# STM32N645 register map
File version: 1.0
CPU: CM55 r0p1, little endian, no MPU, FPU, vendor SysTick, 8 interrupt priority bits
Registers are 32-bit, read-write, reset 0x0 unless marked. A register's access mark holds for its fields unless they carry their own. Offsets are from the block's base; [hi:lo] are bit positions; lines under a group give offsets from that group; {n}, {i} and the like mark numbered series.

## I3C1 — Improved inter-integrated circuit
Base 0x40006000
Same registers: I3C2 0x40006400, I3C1_S 0x50006000, I3C2_S 0x50006400
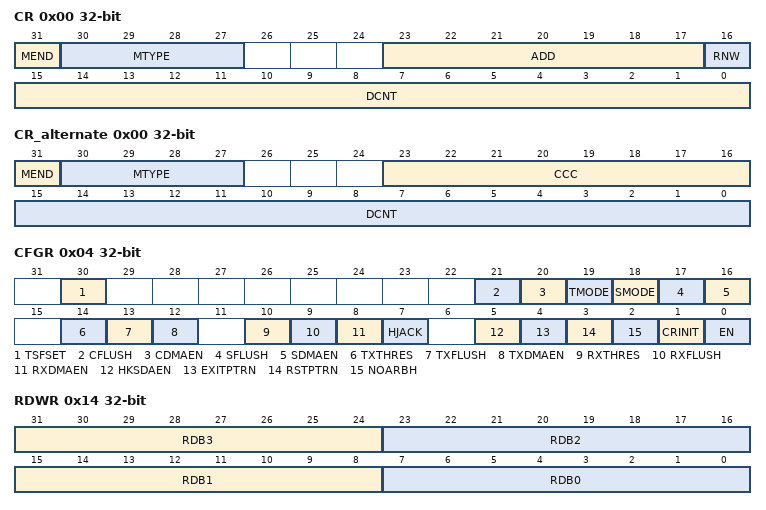
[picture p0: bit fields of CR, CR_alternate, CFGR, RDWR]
0x00 CR wo — I3C message control register
  [31] MEND — Message end type / last message of a frame (when the I3C acts as controller)
  [30:27] MTYPE — Message type (whatever I3C acts as controller/target)
  [23:17] ADD — 7-bit I3C dynamic / I less than sup>2 less than /sup>C static target address (when I3C acts as controller)
  [16] RNW — Read / non-write message (when I3C acts as controller)
  [15:0] DCNT — Count of data to transfer during a read or write message, in bytes (whatever I3C acts as controller/target)
0x00 CR_alternate wo (alternate view of CR) — I3C message control register
  [31] MEND — Message end type / last message of a frame (when I3C acts as controller)
  [30:27] MTYPE — Message type (when I3C acts as controller)
  [23:16] CCC — 8-bit CCC code (when I3C acts as controller)
  [15:0] DCNT — Count of related data to the CCC command to transfer as CCC defining bytes, or CCC sub-command bytes, or CCC data bytes, in bytes
0x04 CFGR access per field — I3C configuration register
  [30] TSFSET wo — Frame transfer set (software trigger) (when I3C acts as controller)
  [21] CFLUSH wo — C-FIFO flush (when I3C acts as controller)
  [20] CDMAEN rw — C-FIFO DMA request enable (when I3C acts as controller)
  [19] TMODE rw — Transmit mode (when I3C acts as controller)
  [18] SMODE rw — S-FIFO enable / status receive mode (when I3C acts as controller)
  [17] SFLUSH wo — S-FIFO flush (when I3C acts as controller)
  [16] SDMAEN rw — S-FIFO DMA request enable (when I3C acts as controller)
  [14] TXTHRES rw — TX-FIFO threshold (whatever I3C acts as controller/target)
  [13] TXFLUSH wo — TX-FIFO flush (whatever I3C acts as controller/target)
  [12] TXDMAEN rw — TX-FIFO DMA request enable (whatever I3C acts as controller/target)
  [10] RXTHRES rw — RX-FIFO threshold (whatever I3C acts as controller/target)
  [9] RXFLUSH wo — RX-FIFO flush (whatever I3C acts as controller/target)
  [8] RXDMAEN rw — RX-FIFO DMA request enable (whatever I3C acts as controller/target)
  [7] HJACK rw — Hot-join request acknowledge (when I3C acts as a controller)
  [5] HKSDAEN rw — High-keeper enable on SDA line (when I3C acts as a controller)
  [4] EXITPTRN rw — HDR exit pattern enable (when I3C acts as a controller)
  [3] RSTPTRN rw — HDR reset pattern enable (when I3C acts as a controller)
  [2] NOARBH rw — No arbitrable header after a start (when I3C acts as a controller)
  [1] CRINIT rw — Initial controller/target role
  [0] EN rw — I3C enable (whatever I3C acts as controller/target)
0x10 RDR ro — I3C receive data byte register
  [7:0] RDB0 — 8-bit received data on I3C bus.
0x14 RDWR ro — I3C receive data word register
  [31:24] RDB3 — 8-bit received data (latest byte on I3C bus).
  [23:16] RDB2 — 8-bit received data (next byte after RDB1 on I3C bus).
  [15:8] RDB1 — 8-bit received data (next byte after RDB0 on I3C bus).
  [7:0] RDB0 — 8-bit received data (earliest byte on I3C bus).
0x18 TDR wo — I3C transmit data byte register
  [7:0] TDB0 — 8-bit data to transmit on I3C bus.
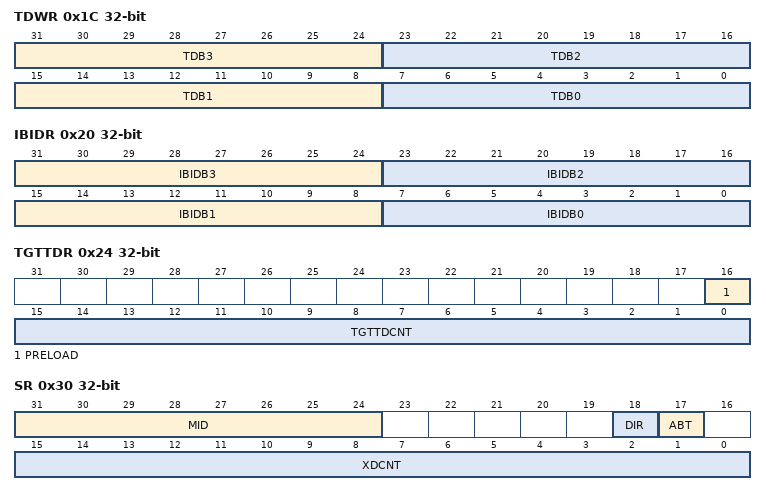
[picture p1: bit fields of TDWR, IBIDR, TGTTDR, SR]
0x1C TDWR wo — I3C transmit data word register
  [31:24] TDB3 — 8-bit transmit data (latest byte on I3C bus).
  [23:16] TDB2 — 8-bit transmit data (next byte after TDB1[7:0] on I3C bus).
  [15:8] TDB1 — 8-bit transmit data (next byte after TDB0[7:0] on I3C bus).
  [7:0] TDB0 — 8-bit transmit data (earliest byte on I3C bus)
0x20 IBIDR — I3C IBI payload data register
  [31:24] IBIDB3 — 8-bit IBI payload data (latest byte on I3C bus).
  [23:16] IBIDB2 — 8-bit IBI payload data (next byte on I3C bus after IBIDB1[7:0]).
  [15:8] IBIDB1 — 8-bit IBI payload data (next byte on I3C bus after IBIDB0[7:0]).
  [7:0] IBIDB0 — 8-bit IBI payload data (earliest byte on I3C bus, MDB[7:0] mandatory data byte).
0x24 TGTTDR — I3C target transmit configuration register
  [16] PRELOAD — Preload of the TX-FIFO (when I3C is configured as target)
  [15:0] TGTTDCNT — Transmit data counter, in bytes (when I3C is configured as target)
0x30 SR ro — I3C status register
  [31:24] MID — Message identifier/counter of a given frame (when the I3C acts as controller)
  [18] DIR — Message direction
  [17] ABT — A private read message is ended prematurely by the target (when the I3C acts as controller)
  [15:0] XDCNT — Data counter
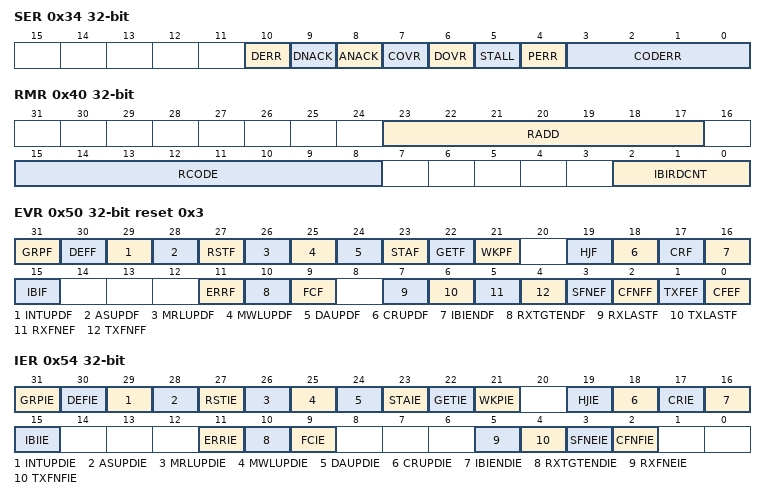
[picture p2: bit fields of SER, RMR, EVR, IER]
0x34 SER ro — I3C status error register
  [10] DERR — Data error (when the I3C acts as controller)
  [9] DNACK — Data not acknowledged (when the I3C acts as controller)
  [8] ANACK — Address not acknowledged (when the I3C is configured as controller)
  [7] COVR — C-FIFO underrun or S-FIFO overrun (when the I3C acts as controller)
  [6] DOVR — RX-FIFO overrun or TX-FIFO underrun
  [5] STALL — SCL stall error (when the I3C acts as target)
  [4] PERR — Protocol error
  [3:0] CODERR — Protocol error code/type
0x40 RMR ro — I3C received message register
  [23:17] RADD — Received target address (when the I3C is configured as controller)
  [15:8] RCODE — Received CCC code (when the I3C is configured as target)
  [2:0] IBIRDCNT — IBI received payload data count (when the I3C is configured as controller)
0x50 EVR ro reset 0x3 — I3C event register
  [31] GRPF — Group addressing flag (when the I3C acts as target)
  [30] DEFF — DEFTGTS flag (when the I3C acts as target)
  [29] INTUPDF — Interrupt/controller-role/hot-join update flag (when the I3C acts as target)
  [28] ASUPDF — Activity state update flag (when the I3C acts as target)
  [27] RSTF — Reset pattern flag (when the I3C acts as target)
  [26] MRLUPDF — Maximum read length update flag (when the I3C acts as target)
  [25] MWLUPDF — Maximum write length update flag (when the I3C acts as target)
  [24] DAUPDF — Dynamic address update flag (when the I3C acts as target)
  [23] STAF — Get status flag (when the I3C acts as target)
  [22] GETF — Get flag (when the I3C acts as target)
  [21] WKPF — Wake-up/missed start flag (when the I3C acts as target)
  [19] HJF — Hot-join flag (when the I3C acts as controller)
  [18] CRUPDF — Controller-role update flag (when the I3C acts as target)
  [17] CRF — Controller-role request flag (when the I3C acts as controller)
  [16] IBIENDF — IBI end flag (when the I3C acts as target)
  [15] IBIF — IBI flag (when the I3C acts as controller)
  [11] ERRF — Flag (whatever the I3C acts as controller/target)
  [10] RXTGTENDF — Target-initiated read end flag (when the I3C acts as controller)
  [9] FCF — Frame complete flag (whatever the I3C acts as controller/target)
  [7] RXLASTF — Last read data byte/word flag (when the I3C acts as controller)
  [6] TXLASTF — Last written data byte/word flag (whatever the I3C acts as controller/target)
  [5] RXFNEF — RX-FIFO not empty flag (whatever the I3C acts as controller/target)
  [4] TXFNFF — TX-FIFO not full flag (whatever the I3C acts as controller/target)
  [3] SFNEF — S-FIFO not empty flag (when the I3C acts as controller)
  [2] CFNFF — C-FIFO not full flag (when the I3C acts as controller)
  [1] TXFEF — TX-FIFO empty flag (whatever the I3C acts as controller/target)
  [0] CFEF — C-FIFO empty flag (whatever the I3C acts as controller)
0x54 IER ro — I3C interrupt enable register
  [31] GRPIE — DEFGRPA CCC interrupt enable (when the I3C acts as target)
  [30] DEFIE — DEFTGTS CCC interrupt enable (when the I3C acts as target)
  [29] INTUPDIE — ENEC/DISEC CCC interrupt enable (when the I3C acts as target)
  [28] ASUPDIE — ENTASx CCC interrupt enable (when the I3C acts as target)
  [27] RSTIE — reset pattern interrupt enable (when the I3C acts as target)
  [26] MRLUPDIE — SETMRL CCC interrupt enable (when the I3C acts as target)
  [25] MWLUPDIE — SETMWL CCC interrupt enable (when the I3C acts as target)
  [24] DAUPDIE — ENTDAA/RSTDAA/SETNEWDA CCC interrupt enable (when the I3C acts as target)
  [23] STAIE — format 1 GETSTATUS CCC interrupt enable (when the I3C acts as target)
  [22] GETIE — GETxxx CCC interrupt enable (except GETSTATUS of format 1) (when the I3C acts as target)
  [21] WKPIE — Wake-up interrupt enable (when the I3C acts as target)
  [19] HJIE — Hot-join interrupt enable (when the I3C acts as controller)
  [18] CRUPDIE — Controller-role update interrupt enable (when the I3C acts as target)
  [17] CRIE — Controller-role request interrupt enable (when the I3C acts as controller)
  [16] IBIENDIE — IBI end interrupt enable (when the I3C acts as target)
  [15] IBIIE — IBI request interrupt enable (when the I3C acts as controller)
  [11] ERRIE — error interrupt enable (whatever the I3C acts as controller/target)
  [10] RXTGTENDIE — target-initiated read end interrupt enable (when the I3C acts as controller)
  [9] FCIE — frame complete interrupt enable (whatever the I3C acts as controller/target)
  [5] RXFNEIE — RX-FIFO not empty interrupt enable (whatever the I3C acts as controller/target)
  [4] TXFNFIE — TX-FIFO not full interrupt enable (whatever the I3C acts as controller/target)
  [3] SFNEIE — S-FIFO not empty interrupt enable (whatever the I3C acts as controller/target)
  [2] CFNFIE — C-FIFO not full interrupt enable (whatever the I3C acts as controller/target)
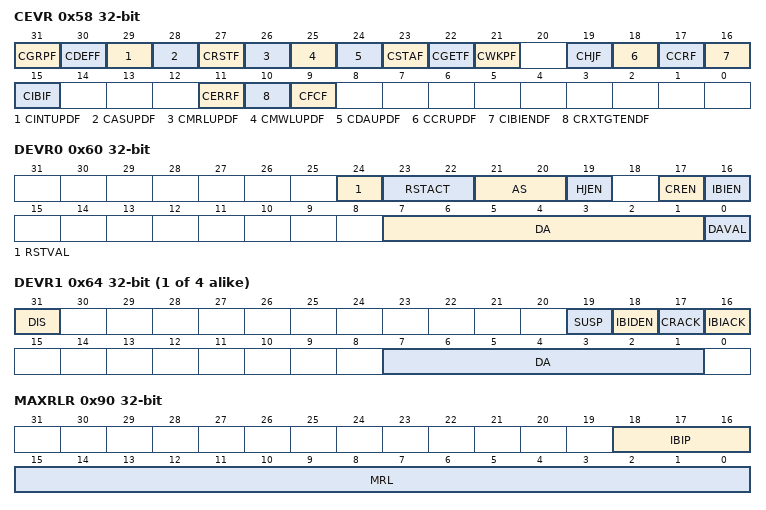
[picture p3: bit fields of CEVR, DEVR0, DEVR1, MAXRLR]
0x58 CEVR wo — I3C clear event register
  [31] CGRPF — Clear DEFGRPA CCC flag (when the I3C acts as target)
  [30] CDEFF — Clear DEFTGTS CCC flag (when the I3C acts as target)
  [29] CINTUPDF — Clear ENEC/DISEC CCC flag (when the I3C acts as target)
  [28] CASUPDF — Clear ENTASx CCC flag (when the I3C acts as target)
  [27] CRSTF — Clear reset pattern flag (when the I3C acts as target)
  [26] CMRLUPDF — Clear SETMRL CCC flag (when the I3C acts as target)
  [25] CMWLUPDF — Clear SETMWL CCC flag (when the I3C acts as target)
  [24] CDAUPDF — Clear ENTDAA/RSTDAA/SETNEWDA CCC flag (when the I3C acts as target)
  [23] CSTAF — Clear format 1 GETSTATUS CCC flag (when the I3C acts as target)
  [22] CGETF — Clear GETxxx CCC flag (except GETSTATUS of format 1) (when the I3C acts as target)
  [21] CWKPF — Clear wake-up flag (when the I3C acts as target)
  [19] CHJF — Clear hot-join flag (when the I3C acts as controller)
  [18] CCRUPDF — Clear controller-role update flag (when the I3C acts as target)
  [17] CCRF — Clear controller-role request flag (when the I3C acts as controller)
  [16] CIBIENDF — Clear IBI end flag (when the I3C acts as target)
  [15] CIBIF — Clear IBI request flag (when the I3C acts as controller)
  [11] CERRF — Clear error flag (whatever the I3C acts as controller/target)
  [10] CRXTGTENDF — Clear target-initiated read end flag (when the I3C acts as controller)
  [9] CFCF — Clear frame complete flag (whatever the I3C acts as controller/target)
0x60 DEVR0 access per field — I3C own device characteristics register
  [24] RSTVAL ro — Reset action is valid (when the I3C acts as target)
  [23:22] RSTACT ro — Reset action/level on received reset pattern (when the I3C acts as target)
  [21:20] AS ro — Activity state (when the I3C acts as target)
  [19] HJEN rw — Hot-join request enable (when the I3C acts as target)
  [17] CREN rw — Controller-role request enable (when the I3C acts as target)
  [16] IBIEN rw — IBI request enable (when the I3C acts as target)
  [7:1] DA rw — 7-bit dynamic address
  [0] DAVAL rw — Dynamic address is valid (when the I3C acts as target)
{0x60+4i} DEVR{i} access per field (i=1..4) — I3C device {i} characteristics register
  [31] DIS ro — DA[6:0] write disabled (when the I3C acts as controller)
  [19] SUSP rw — Suspend/stop I3C transfer on received IBI (when the I3C acts as controller)
  [18] IBIDEN rw — IBI data enable (when the I3C acts as controller)
  [17] CRACK rw — Controller-role request acknowledge (when the I3C acts as controller)
  [16] IBIACK rw — IBI request acknowledge (when the I3C acts as controller)
  [7:1] DA rw — Assigned I3C dynamic address to target x (when the I3C acts as controller)
0x90 MAXRLR — I3C maximum read length register
  [18:16] IBIP — IBI payload data maximum size, in bytes (when I3C acts as target)
  [15:0] MRL — Maximum data read length (when I3C acts as target)
0x94 MAXWLR — I3C maximum write length register
  [15:0] MWL — Maximum data write length (when I3C acts as target)
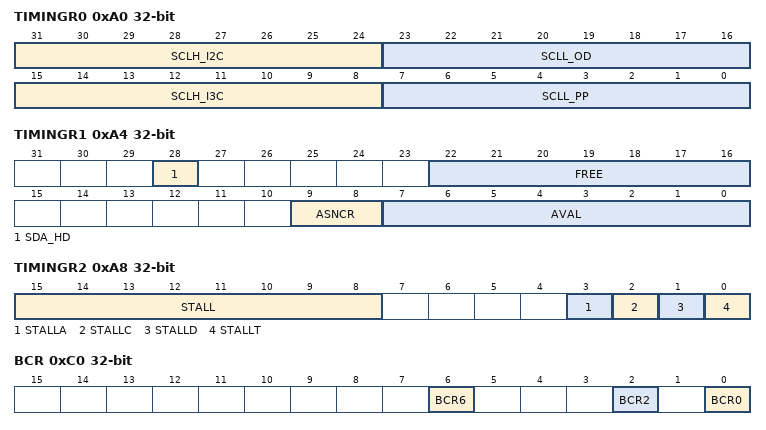
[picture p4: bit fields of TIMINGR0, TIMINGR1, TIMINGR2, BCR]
0xA0 TIMINGR0 — I3C timing register 0
  [31:24] SCLH_I2C — SCL high duration, used for legacy I less than sup>2 less than /sup>C messages, in number of kernel clocks cycles:
  [23:16] SCLL_OD — SCL low duration in open-drain phases, used for legacy I less than sup>2 less than /sup>C messages and for I3C open-drain phases (address phase following a start, ACK phase during controller-initiated messages, and T bit phase during direct/private/IBI payload), in number of kernel clocks cycles:
  [15:8] SCLH_I3C — SCL high duration, used for I3C messages (both in push-pull and open-drain phases), in number of kernel clocks cycles:
  [7:0] SCLL_PP — SCL low duration in I3C push-pull phases, in number of kernel clocks cycles:
0xA4 TIMINGR1 — I3C timing register 1
  [28] SDA_HD — SDA hold time (when the I3C acts as controller), in number of kernel clocks cycles (refer to MIPI timing SDA hold time in push-pull t less than sub>HD_PP less than /sub>):
  [22:16] FREE — Number of kernel clocks cycles that is used to set some MIPI timings like bus free condition time (when the I3C acts as controller)
  [9:8] ASNCR — Activity state of the new controller (when I3C acts as active controller)
  [7:0] AVAL — Number of kernel clock cycles to set a time unit of 1 s, whatever I3C acts as controller or target.
0xA8 TIMINGR2 — I3C timing register 2
  [15:8] STALL — Controller clock stall time, in number of kernel clock cycles
  [3] STALLA — Controller clock stall enable on ACK phase
  [2] STALLC — Controller clock stall enable on PAR phase of CCC
  [1] STALLD — Controller clock stall enable on PAR phase of Data
  [0] STALLT — Controller clock stall enable on T-bit phase of data (and on the ACK/NACK phase of data byte of a legacy I less than sup>2 less than /sup>C read)
0xC0 BCR — I3C bus characteristics register
  [6] BCR6 — Controller capable
  [2] BCR2 — in-band interrupt (IBI) payload
  [0] BCR0 — max data speed limitation
0xC4 DCR — I3C device characteristics register
  [7:0] DCR — device characteristics ID
0xC8 GETCAPR — I3C get capability register
  [14] CAPPEND — IBI MDB support for pending read notification
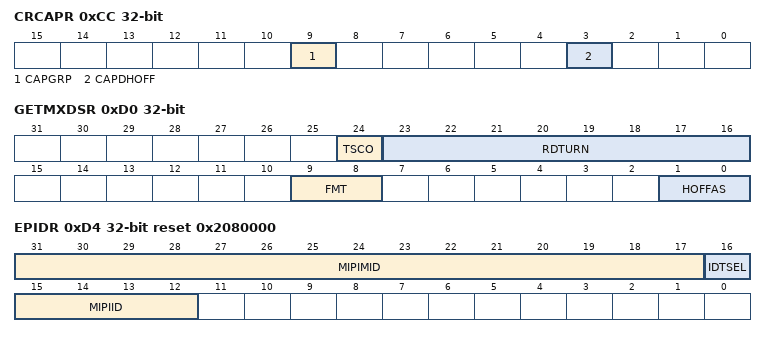
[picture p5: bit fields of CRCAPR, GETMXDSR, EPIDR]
0xCC CRCAPR — I3C controller-role capability register
  [9] CAPGRP — group management support (when acting as controller)
  [3] CAPDHOFF — delayed controller-role hand-off
0xD0 GETMXDSR — I3C get capability register
  [24] TSCO — clock-to-data turnaround time (t less than sub>SCO less than /sub>)
  [23:16] RDTURN — programmed byte of the 3-byte MaxRdTurn (maximum read turnaround byte)
  [9:8] FMT — GETMXDS CCC format
  [1:0] HOFFAS — Controller hand-off activity state
0xD4 EPIDR access per field reset 0x2080000 — I3C extended provisioned ID register
  [31:17] MIPIMID ro — 15-bit MIPI manufacturer ID
  [16] IDTSEL ro — provisioned ID type selector
  [15:12] MIPIID rw — 4-bit MIPI Instance ID
